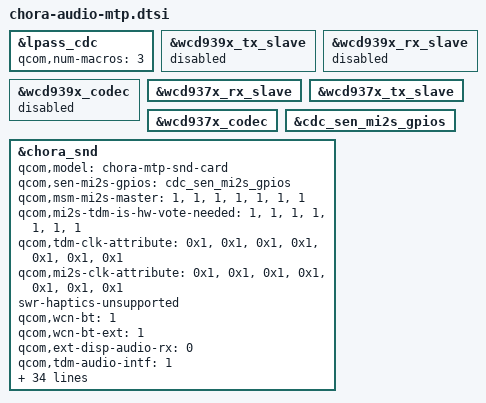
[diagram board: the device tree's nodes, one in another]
// SPDX-License-Identifier: BSD-3-Clause
/*
 * Copyright (c) Qualcomm Technologies, Inc. and/or its subsidiaries.
 */

#include "lpass-audio-cdc-1.0.dtsi"
#include "chora-lpi.dtsi"
#include "lpass-audio-bt-swr.dtsi"
#include "lpass-cdc-gpio.dtsi"
#include "chora-audio-lpass-reg.dtsi"
#include "wcd939x.dtsi"

&lpass_cdc {
	qcom,num-macros = <3>;
};

&wcd939x_tx_slave {
	status = "disabled";
};

&wcd939x_rx_slave {
	status = "disabled";
};

&wcd939x_codec {
	status = "disabled";
};

&wcd937x_rx_slave {
	status = "okay";
};

&wcd937x_tx_slave {
	status = "okay";
};

&wcd937x_codec {
	status = "okay";
};

&cdc_sen_mi2s_gpios {
	status = "okay";
};

&chora_snd {
	qcom,model = "chora-mtp-snd-card";
	qcom,sen-mi2s-gpios = <&cdc_sen_mi2s_gpios>;
	qcom,msm-mi2s-master = <1>, <1>, <1>, <1>, <1>, <1>, <1>;
	qcom,mi2s-tdm-is-hw-vote-needed = <1>, <1>, <1>, <1>, <1>, <1>, <1>;
	qcom,tdm-clk-attribute = <0x1>, <0x1>, <0x1>, <0x1>, <0x1>, <0x1>, <0x1>;
	qcom,mi2s-clk-attribute = <0x1>, <0x1>, <0x1>, <0x1>, <0x1>, <0x1>, <0x1>;
	swr-haptics-unsupported;
	qcom,wcn-bt = <1>;
	qcom,wcn-bt-ext = <1>;
	qcom,ext-disp-audio-rx = <0>;
	qcom,tdm-audio-intf = <1>;
	qcom,wsa885x-tdm = <1>;
	qcom,audio-core-list = <0>, <1>;
	qcom,msm-mbhc-hs-mic-max-threshold-mv = <1670>;
	qcom,msm-mbhc-usbc-audio-supported = <0>;
	qcom,msm-mbhc-hphl-swh = <1>;
	qcom,msm-mbhc-gnd-swh = <1>;
	asoc-codec  = <&stub_codec>, <&lpass_cdc>,
			<&wcd937x_codec>, <&wsa885x_i2c>;
	asoc-codec-names = "msm-stub-codec.1", "lpass-cdc",
			"wcd937x_codec", "wsa885x_i2c";
	qcom,audio-routing =
			"AMIC2", "Analog Mic2",
			"AMIC2", "MIC BIAS2",
			"TX DMIC0", "Digital Mic0",
			"TX DMIC0", "MIC BIAS3",
			"TX DMIC1", "Digital Mic1",
			"TX DMIC1", "MIC BIAS3",
			"TX DMIC2", "Digital Mic2",
			"TX DMIC2", "MIC BIAS1",
			"TX DMIC3", "Digital Mic3",
			"TX DMIC3", "MIC BIAS1",
			"IN1_HPHL", "HPHL_OUT",
			"IN2_HPHR", "HPHR_OUT",
			"IN3_AUX", "AUX_OUT",
			"TX SWR_INPUT", "WCD_TX_OUTPUT",
			"VA SWR_INPUT", "VA_SWR_CLK",
			"VA SWR_INPUT", "WCD_TX_OUTPUT",
			"VA_AIF1 CAP", "VA_SWR_CLK",
			"VA_AIF2 CAP", "VA_SWR_CLK",
			"VA_AIF3 CAP", "VA_SWR_CLK",
			"VA DMIC0", "Digital Mic0",
			"VA DMIC1", "Digital Mic1",
			"VA DMIC2", "Digital Mic2",
			"VA DMIC3", "Digital Mic3",
			"VA DMIC0", "VA MIC BIAS3",
			"VA DMIC1", "VA MIC BIAS3",
			"VA DMIC2", "VA MIC BIAS1",
			"VA DMIC3", "VA MIC BIAS1";
	qcom,wsa-max-devs = <0>;
	qcom,cdc-dmic01-gpios = <&cdc_dmic01_gpios>;
	qcom,cdc-dmic23-gpios = <&cdc_dmic23_gpios>;
	qcom,msm_audio_ssr_devs = <&audio_gpr>, <&lpi_tlmm>,
				  <&lpass_cdc>, <&lpass_bt_swr>;

		/*
		 * ====================
		 * UPD backend - WSA
		 * ====================
		 *
		 * Mute/Unmute the interpolator
		 * ------------------------------
		 * Register:Â LPASS_WSA_CDC_RX0_RX_PATH_MIX_CTL - 0x6B00418
		 *
		 * Send control commands to the peripheral from the soundwire controller
		 * -----------------------------------------------------------------------
		 * Register: LPASS_WSA_SWR_MSTR_WSA_SWRM_CPUn_CMD_FIFO_WR_CMD - 0x6B14020
		 *
		 * Enable/Disable ear piece
		 * --------------------------
		 * Register:Â DIG_CTRL0_PA_FSM_EN - 0x3430
		 *
		 *
		 *	qcom,upd_backends_used = "wsa";
		 *	qcom,upd_lpass_reg_addr = <0x6B00418 0x6B14020>;
		 *	qcom,upd_ear_pa_reg_addr = <0x3430>;
		 *
		 *
		 * ====================
		 * UPD backend - WCD
		 * ====================
		 *
		 * Mute/Unmute the interpolator
		 * ------------------------------
		 * Register: LPASS_WCD_CDC_RX0_RX_PATH_MIX_CTL - 0x6AC0418
		 *
		 * Send control commands to the wcd from the soundwire controller
		 * ----------------------------------------------------------------
		 * Register: LPASS_WCD_SWR_MSTR_WSA_SWRM_CPUn_CMD_FIFO_WR_CMD - 0x7634020
		 *
		 * Enable/Disable ear piece
		 * --------------------------
		 * Register:Â DIG_CTRL0_PA_FSM_EN - 0x300A
		 *
		 */
	qcom,upd_backends_used = "wcd";
	qcom,upd_lpass_reg_addr = <0x3200418 0x33B0300>;
	qcom,upd_ear_pa_reg_addr = <0x300A>;
};

